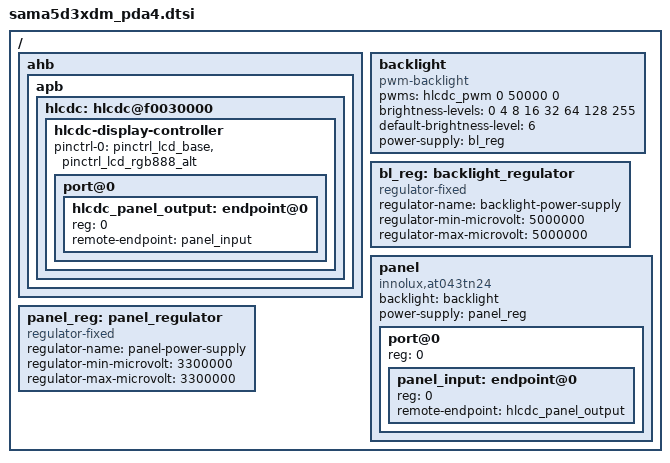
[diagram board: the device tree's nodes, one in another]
/*
 * sama5d3xdm_pda4.dtsi - Device Tree file for SAMA5 display module
 *
 *  Copyright (C) 2014 Atmel,
 *                2014 Ludovic Desroches <ludovic.desroches@atmel.com>
 *
 * Licensed under GPLv2 or later.
 */

/ {
	ahb {
		apb {
			hlcdc: hlcdc@f0030000 {
				status = "okay";

				hlcdc-display-controller {
					pinctrl-names = "default";
					pinctrl-0 = <&pinctrl_lcd_base &pinctrl_lcd_rgb888_alt>;

					port@0 {
						hlcdc_panel_output: endpoint@0 {
							reg = <0>;
							remote-endpoint = <&panel_input>;
						};
					};
				};
			};

		};
	};

	backlight: backlight {
		compatible = "pwm-backlight";
		pwms = <&hlcdc_pwm 0 50000 0>;
		brightness-levels = <0 4 8 16 32 64 128 255>;
		default-brightness-level = <6>;
		power-supply = <&bl_reg>;
		status = "okay";
	};

	bl_reg: backlight_regulator {
		compatible = "regulator-fixed";
		regulator-name = "backlight-power-supply";
		regulator-min-microvolt = <5000000>;
		regulator-max-microvolt = <5000000>;
		status = "okay";
	};

	panel: panel {
		compatible = "innolux,at043tn24", "simple-panel";
		backlight = <&backlight>;
		power-supply = <&panel_reg>;
		#address-cells = <1>;
		#size-cells = <0>;
		status = "okay";

		port@0 {
			reg = <0>;
			#address-cells = <1>;
			#size-cells = <0>;

			panel_input: endpoint@0 {
				reg = <0>;
				remote-endpoint = <&hlcdc_panel_output>;
			};
		};
	};

	panel_reg: panel_regulator {
		compatible = "regulator-fixed";
		regulator-name = "panel-power-supply";
		regulator-min-microvolt = <3300000>;
		regulator-max-microvolt = <3300000>;
		status = "okay";
	};
};
